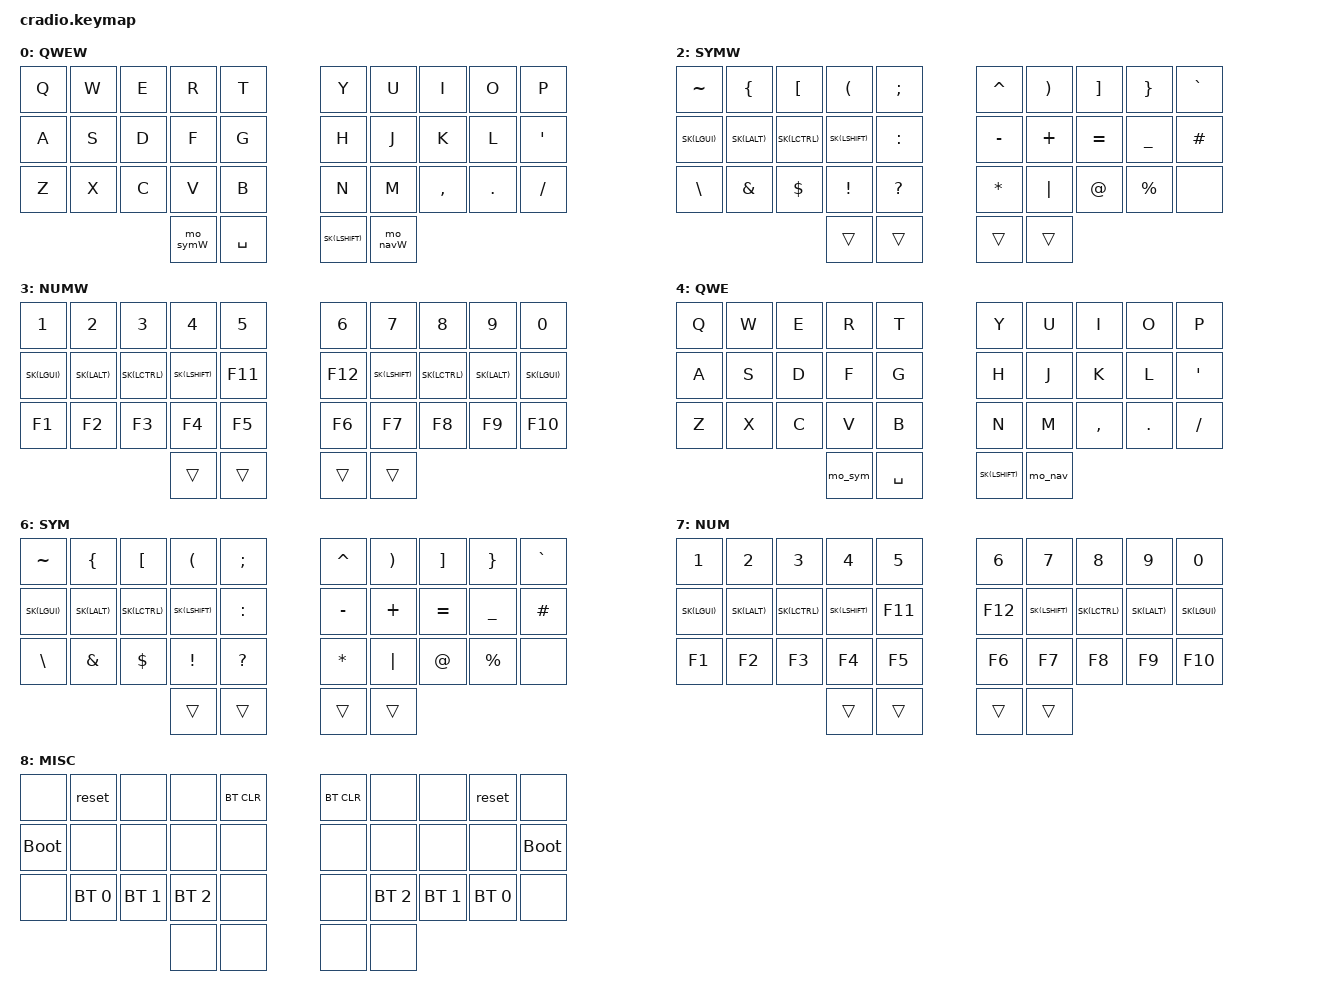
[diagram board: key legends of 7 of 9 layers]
/*
 * Copyright (c) 2020 The ZMK Contributors
 *
 * SPDX-License-Identifier: MIT
 */

#include <behaviors.dtsi>
#include <dt-bindings/zmk/keys.h>
#include <dt-bindings/zmk/bt.h>
#include <dt-bindings/zmk/outputs.h>

#define QWEW 0
#define NAVW 1
#define SYMW 2
#define NUMW 3
#define QWE 4
#define NAV 5
#define SYM 6
#define NUM 7
#define MISC 8

#define SK(KEY) &nk KEY KEY
// Keep sticky keys active for a long time so they effectively do not time out
#define STICKY_KEY_TIMEOUT 60000

&sk {
  release-after-ms = <STICKY_KEY_TIMEOUT>;
};

&caps_word {
  continue-list = <UNDERSCORE MINUS BACKSPACE>;
};

/* KEY POSITIONS
    ╭────────────────────╮ ╭────────────────────╮
    │  0   1   2   3   4 │ │  5   6   7   8   9 │
    │ 10  11  12  13  14 │ │ 15  16  17  18  19 │
    │ 20  21  22  23  24 │ │ 25  26  27  28  29 │
    ╰───────────╮ 30  31 │ │ 32  33 ╭───────────╯
                ╰────────╯ ╰────────╯
*/

/ { 
  
  behaviors {

    // Sticky key on tap, normal key on hold
    // Useful for modifier-clicking without the modifier remaining active
    nk: not_so_sticky_key {
      compatible = "zmk,behavior-hold-tap";
      label = "NOT_SO_STICKY_KEY";
      #binding-cells = <2>;
      tapping_term_ms = <169>;
      flavor = "tap-preferred";
      bindings = <&kp>, <&sk>;
    };

     ZMK_MACRO(mo_nav,
        wait-ms = <0>;
        tap-ms = <0>;
        bindings
        = <&macro_tap &kp K_CANCEL>
        , <&macro_press &mo NAV>
        , <&macro_pause_for_release>
        , <&macro_release &mo NAV>;)

     ZMK_MACRO(mo_sym,
        wait-ms = <0>;
        tap-ms = <0>;
        bindings
        = <&macro_tap &kp K_CANCEL>
        , <&macro_press &mo SYM>
        , <&macro_pause_for_release>
        , <&macro_release &mo SYM>;)

     ZMK_MACRO(mo_navW,
        wait-ms = <0>;
        tap-ms = <0>;
        bindings
        = <&macro_tap &kp K_CANCEL>
        , <&macro_press &mo NAVW>
        , <&macro_pause_for_release>
        , <&macro_release &mo NAVW>;)

     ZMK_MACRO(mo_symW,
        wait-ms = <0>;
        tap-ms = <0>;
        bindings
        = <&macro_tap &kp K_CANCEL>
        , <&macro_press &mo SYMW>
        , <&macro_pause_for_release>
        , <&macro_release &mo SYMW>;)

  combos {
    #include "combos.dtsi"
  };


  };

     cond_layers {
        compatible = "zmk,conditional-layers";
        num {
            if-layers = <NAV SYM>;
            then-layer = <NUM>;
        };
      
        numw {
            if-layers = <NAVW SYMW>;
            then-layer = <NUMW>;
        };
    };
 
        keymap {
                compatible = "zmk,keymap";
              
         qwerty_windows {
            label = "QWEW";
            bindings = <
// ╭─────────────┬─────────────┬─────────────┬─────────────┬─────────────╮   ╭─────────────┬─────────────┬─────────────┬─────────────┬─────────────╮
     &kp Q         &kp W         &kp E         &kp R         &kp T             &kp Y         &kp U         &kp I         &kp O         &kp P
// ├─────────────┼─────────────┼─────────────┼─────────────┼─────────────┤   ├─────────────┼─────────────┼─────────────┼─────────────┼─────────────┤
     &kp A         &kp S         &kp D         &kp F         &kp G             &kp H         &kp J         &kp K         &kp L         &kp QUOT
// ├─────────────┼─────────────┼─────────────┼─────────────┼─────────────┤   ├─────────────┼─────────────┼─────────────┼─────────────┼─────────────┤
     &kp Z         &kp X         &kp C         &kp V         &kp B             &kp N         &kp M         &kp COMMA     &kp DOT       &kp SLASH
// ╰─────────────┴─────────────┴─────────────┼─────────────┼─────────────┤   ├─────────────┼─────────────┼─────────────┴─────────────┴─────────────╯
                                               &mo_symW      &kp SPACE         SK(LSHIFT)    &mo_navW
//                                           ╰─────────────┴─────────────╯   ╰─────────────┴─────────────╯
            >;
        };
        navigation_windows {
            label = "NAVW";
            bindings = <
// ╭─────────────┬─────────────┬─────────────┬─────────────┬─────────────╮   ╭─────────────┬─────────────┬─────────────┬─────────────┬─────────────╮
     &kp LA(F4)     &kp DELETE    &kp UP         &kp ESCAPE    &kp LC(F)         &kp LC(Z)     &kp LC(X)     &kp LC(C)     &kp LC(V)     &kp LC(Y)
// ├─────────────┼─────────────┼─────────────┼─────────────┼─────────────┤   ├─────────────┼─────────────┼─────────────┼─────────────┼─────────────┤
     &kp TAB       &kp LEFT      &kp DOWN       &kp RIGHT     &kp BACKSPACE     &kp LC(A)     SK(LSHIFT)    SK(LCTRL)     SK(LALT)      SK(LGUI)
// ├─────────────┼─────────────┼─────────────┼─────────────┼─────────────┤   ├─────────────┼─────────────┼─────────────┼─────────────┼─────────────┤
&kp LG(LS(LEFT)) &kp LG(LS(RIGHT)) &kp LG(UP) &kp LG(TAB)     &kp ENTER         &kp LC(LS(T)) &kp LC(W)     &kp LC(R)     &kp LC(T)       &kp LC(LA(LS(P)))
// ╰─────────────┴─────────────┴─────────────┼─────────────┼─────────────┤   ├─────────────┼─────────────┼─────────────┴─────────────┴─────────────╯
                                              &trans          &kp LANG1            &trans        &trans
//                                           ╰─────────────┴─────────────╯   ╰─────────────┴─────────────╯
            >;
        };
        symbols_windows {
            label = "SYMW";
            bindings = <
// ╭─────────────┬─────────────┬─────────────┬─────────────┬─────────────╮   ╭─────────────┬─────────────┬─────────────┬─────────────┬─────────────╮
     &kp TILDE     &kp LBRC      &kp LBKT      &kp LPAR      &kp SEMI          &kp CARET     &kp RPAR      &kp RBKT      &kp RBRC      &kp GRAVE
// ├─────────────┼─────────────┼─────────────┼─────────────┼─────────────┤   ├─────────────┼─────────────┼─────────────┼─────────────┼─────────────┤
     SK(LGUI)      SK(LALT)      SK(LCTRL)     SK(LSHIFT)    &kp COLON         &kp MINUS     &kp PLUS      &kp EQUAL     &kp UNDER     &kp HASH
// ├─────────────┼─────────────┼─────────────┼─────────────┼─────────────┤   ├─────────────┼─────────────┼─────────────┼─────────────┼─────────────┤
     &kp BSLH      &kp AMPS      &kp DLLR      &kp EXCL      &kp QMARK         &kp ASTRK     &kp PIPE      &kp AT        &kp PRCNT     &none
// ╰─────────────┴─────────────┴─────────────┼─────────────┼─────────────┤   ├─────────────┼─────────────┼─────────────┴─────────────┴─────────────╯
                                              &trans          &trans            &trans        &trans
//                                           ╰─────────────┴─────────────╯   ╰─────────────┴─────────────╯
            >;
        };
        numbers_windows {
            label = "NUMW";
            bindings = <
// ╭─────────────┬─────────────┬─────────────┬─────────────┬─────────────╮   ╭─────────────┬─────────────┬─────────────┬─────────────┬─────────────╮
     &kp N1        &kp N2        &kp N3        &kp N4        &kp N5            &kp N6        &kp N7       &kp N8         &kp N9        &kp N0
// ├─────────────┼─────────────┼─────────────┼─────────────┼─────────────┤   ├─────────────┼─────────────┼─────────────┼─────────────┼─────────────┤
     SK(LGUI)      SK(LALT)      SK(LCTRL)     SK(LSHIFT)    &kp F11           &kp F12       SK(LSHIFT)    SK(LCTRL)     SK(LALT)      SK(LGUI)
// ├─────────────┼─────────────┼─────────────┼─────────────┼─────────────┤   ├─────────────┼─────────────┼─────────────┼─────────────┼─────────────┤
     &kp F1        &kp F2        &kp F3        &kp F4        &kp F5            &kp F6        &kp F7        &kp F8         &kp F9        &kp F10
// ╰─────────────┴─────────────┴─────────────┼─────────────┼─────────────┤   ├─────────────┼─────────────┼─────────────┴─────────────┴─────────────╯
                                              &trans          &trans            &trans        &trans
//                                           ╰─────────────┴─────────────╯   ╰─────────────┴─────────────╯
           
            >;
        };
         qwerty {
            label = "QWE";
            bindings = <
// ╭─────────────┬─────────────┬─────────────┬─────────────┬─────────────╮   ╭─────────────┬─────────────┬─────────────┬─────────────┬─────────────╮
     &kp Q         &kp W         &kp E         &kp R         &kp T             &kp Y         &kp U         &kp I         &kp O         &kp P
// ├─────────────┼─────────────┼─────────────┼─────────────┼─────────────┤   ├─────────────┼─────────────┼─────────────┼─────────────┼─────────────┤
     &kp A         &kp S         &kp D         &kp F         &kp G             &kp H         &kp J         &kp K         &kp L         &kp QUOT
// ├─────────────┼─────────────┼─────────────┼─────────────┼─────────────┤   ├─────────────┼─────────────┼─────────────┼─────────────┼─────────────┤
     &kp Z         &kp X         &kp C         &kp V         &kp B             &kp N         &kp M         &kp COMMA     &kp DOT       &kp SLASH
// ╰─────────────┴─────────────┴─────────────┼─────────────┼─────────────┤   ├─────────────┼─────────────┼─────────────┴─────────────┴─────────────╯
                                              &mo_sym        &kp SPACE         SK(LSHIFT)    &mo_nav
//                                           ╰─────────────┴─────────────╯   ╰─────────────┴─────────────╯
            >;
        };

        navitation {
            label = "NAV";
            bindings = <
// ╭─────────────┬─────────────┬─────────────┬─────────────┬─────────────╮   ╭─────────────┬─────────────┬─────────────┬─────────────┬─────────────╮
     &kp LG(Q)     &kp DELETE    &kp UP         &kp ESCAPE    &kp LG(F)         &kp LG(Z)     &kp LG(X)     &kp LG(C)     &kp LG(V)     &kp LG(LS(Z))
// ├─────────────┼─────────────┼─────────────┼─────────────┼─────────────┤   ├─────────────┼─────────────┼─────────────┼─────────────┼─────────────┤
     &kp TAB       &kp LEFT      &kp DOWN       &kp RIGHT     &kp BACKSPACE     &kp LG(A)     SK(LSHIFT)    SK(LCTRL)     SK(LALT)      SK(LGUI)
// ├─────────────┼─────────────┼─────────────┼─────────────┼─────────────┤   ├─────────────┼─────────────┼─────────────┼─────────────┼─────────────┤
&kp LA(LC(LEFT)) &kp LA(LC(RIGHT)) &kp LA(LC(ENTER)) &kp LA(LG(I)) &kp ENTER    &kp LG(LS(T)) &kp LG(W)     &kp LG(R)     &kp LG(T)     &kp LG(LC(LA(LS(P))))
// ╰─────────────┴─────────────┴─────────────┼─────────────┼─────────────┤   ├─────────────┼─────────────┼─────────────┴─────────────┴─────────────╯
                                              &trans         &kp LANG1            &trans        &trans
//                                           ╰─────────────┴─────────────╯   ╰─────────────┴─────────────╯
            >;
        };
        symbols {
            label = "SYM";
            bindings = <
// ╭─────────────┬─────────────┬─────────────┬─────────────┬─────────────╮   ╭─────────────┬─────────────┬─────────────┬─────────────┬─────────────╮
     &kp TILDE     &kp LBRC      &kp LBKT      &kp LPAR      &kp SEMI          &kp CARET     &kp RPAR      &kp RBKT      &kp RBRC      &kp GRAVE
// ├─────────────┼─────────────┼─────────────┼─────────────┼─────────────┤   ├─────────────┼─────────────┼─────────────┼─────────────┼─────────────┤
     SK(LGUI)      SK(LALT)      SK(LCTRL)     SK(LSHIFT)    &kp COLON         &kp MINUS     &kp PLUS      &kp EQUAL     &kp UNDER     &kp HASH
// ├─────────────┼─────────────┼─────────────┼─────────────┼─────────────┤   ├─────────────┼─────────────┼─────────────┼─────────────┼─────────────┤
     &kp BSLH      &kp AMPS      &kp DLLR      &kp EXCL      &kp QMARK         &kp ASTRK     &kp PIPE      &kp AT        &kp PRCNT     &none
// ╰─────────────┴─────────────┴─────────────┼─────────────┼─────────────┤   ├─────────────┼─────────────┼─────────────┴─────────────┴─────────────╯
                                              &trans          &trans            &trans        &trans
//                                           ╰─────────────┴─────────────╯   ╰─────────────┴─────────────╯
            >;
        };
        numbers {
            label = "NUM";
            bindings = <
// ╭─────────────┬─────────────┬─────────────┬─────────────┬─────────────╮   ╭─────────────┬─────────────┬─────────────┬─────────────┬─────────────╮
     &kp N1        &kp N2        &kp N3        &kp N4        &kp N5            &kp N6        &kp N7       &kp N8         &kp N9        &kp N0
// ├─────────────┼─────────────┼─────────────┼─────────────┼─────────────┤   ├─────────────┼─────────────┼─────────────┼─────────────┼─────────────┤
     SK(LGUI)      SK(LALT)      SK(LCTRL)     SK(LSHIFT)    &kp F11           &kp F12       SK(LSHIFT)    SK(LCTRL)     SK(LALT)      SK(LGUI)
// ├─────────────┼─────────────┼─────────────┼─────────────┼─────────────┤   ├─────────────┼─────────────┼─────────────┼─────────────┼─────────────┤
     &kp F1        &kp F2        &kp F3        &kp F4        &kp F5            &kp F6        &kp F7        &kp F8         &kp F9        &kp F10
// ╰─────────────┴─────────────┴─────────────┼─────────────┼─────────────┤   ├─────────────┼─────────────┼─────────────┴─────────────┴─────────────╯
                                              &trans          &trans            &trans        &trans
//                                           ╰─────────────┴─────────────╯   ╰─────────────┴─────────────╯
            >;
        };

        miscellaneous {
            label = "MISC";
            bindings = <
// ╭─────────────┬─────────────┬─────────────┬─────────────┬─────────────╮   ╭─────────────┬─────────────┬─────────────┬─────────────┬─────────────╮
     &none         &reset        &none         &none         &bt BT_CLR        &bt BT_CLR    &none         &none         &reset         &none   
// ├─────────────┼─────────────┼─────────────┼─────────────┼─────────────┤   ├─────────────┼─────────────┼─────────────┼─────────────┼─────────────┤
     &bootloader   &none         &none         &none         &none             &none         &none        &none          &none          &bootloader
// ├─────────────┼─────────────┼─────────────┼─────────────┼─────────────┤   ├─────────────┼─────────────┼─────────────┼─────────────┼─────────────┤
     &none         &bt BT_SEL 0   &bt BT_SEL 1  &bt BT_SEL 2 &none             &none         &bt BT_SEL 2   &bt BT_SEL 1  &bt BT_SEL 0  &none
// ╰─────────────┴─────────────┴─────────────┼─────────────┼─────────────┤   ├─────────────┼─────────────┼─────────────┴─────────────┴─────────────╯
                                               &none         &none             &none         &none
//                                           ╰─────────────┴─────────────╯   ╰─────────────┴─────────────╯
            >;
        };

};

};
